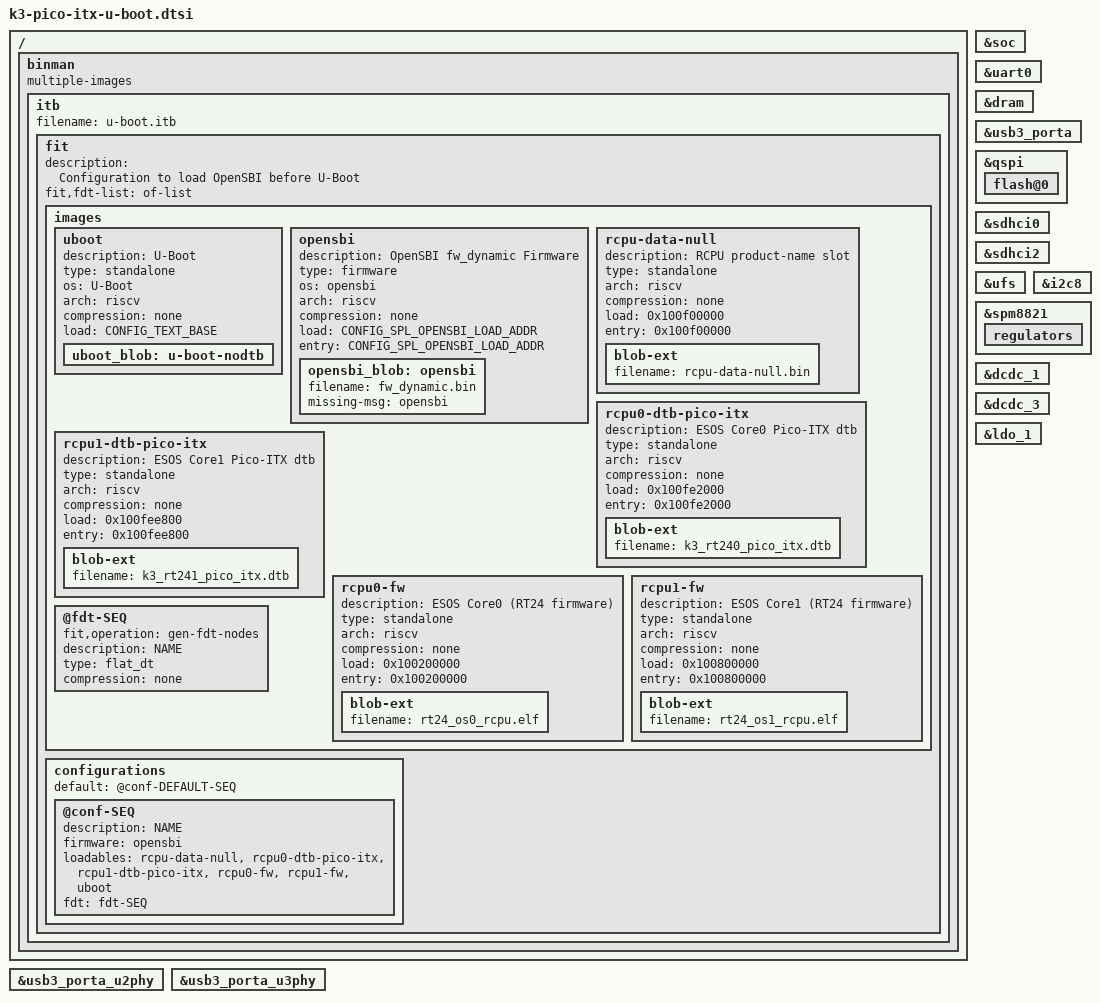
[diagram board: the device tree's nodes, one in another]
// SPDX-License-Identifier: GPL-2.0+ OR MIT
/*
 * Copyright (C) 2025-2026, Spacemit
 *
 * binman description for the SpacemiT K3 (X100) U-Boot FIT (u-boot.itb).
 * The SPL (M-mode, after DDR init) loads this FIT, which carries the OpenSBI
 * fw_dynamic firmware, U-Boot proper as a loadable and the K3 control FDT.
 * Boot chain: SPL -> u-boot.itb -> OpenSBI (M-mode) -> U-Boot proper (S-mode).
 */

#include <config.h>

/*
 * Tag the nodes the SPL (XPL) needs with "bootph-all" so fdtgrep keeps them
 * in the filtered SPL device tree. Upstream U-Boot uses the standardized
 * bootph-* markers (bootph-all = every phase, bootph-pre-ram = SPL); the
 * vendor 2022.10 tree used the old "u-boot,dm-spl", which this fdtgrep
 * ignores. Without these the SPL DTB is stripped to the root node, the DM
 * console never binds (silent SPL) and the DDR UCLASS_RAM probe finds no
 * controller node.
 */
&soc {
	bootph-all;
};

&uart0 {
	bootph-all;
};

&dram {
	bootph-all;
};

&usb3_porta_u2phy {
	bootph-all;
};

&usb3_porta_u3phy {
	bootph-all;
};

&usb3_porta {
	bootph-all;
	/*
	 * The K3 reset controller shares the CCU register base (d4050000) and is
	 * deliberately kept out of the SPL (probing it there disturbs the DDR
	 * clock), so RESET_USB3_PORTA has no provider in the SPL. The BROM already
	 * brought this port out of reset to download the FSBL over USB, so drop
	 * the reset dependency here; otherwise dwc3-generic's reset_get_bulk()
	 * fails and the fastboot gadget never probes.
	 */
	/delete-property/ resets;
	/delete-property/ reset-names;
};

&qspi {
	bootph-all;

	flash@0 {
		bootph-all;
	};
};

&sdhci0 {
	bootph-all;
};

&sdhci2 {
	bootph-all;
};

&ufs {
	bootph-all;
};

&i2c8 {
	bootph-all;
};

&spm8821 {
	bootph-all;

	regulators {
		bootph-all;
	};
};

&dcdc_1 {
	bootph-all;
};

&dcdc_3 {
	bootph-all;
};

&ldo_1 {
	bootph-all;
};

/ {
	binman: binman {
		multiple-images;
	};
};

&binman {
	itb {
		filename = "u-boot.itb";

		fit {
			description = "Configuration to load OpenSBI before U-Boot";
			#address-cells = <2>;
			fit,fdt-list = "of-list";

			images {
				uboot {
					description = "U-Boot";
					type = "standalone";
					os = "U-Boot";
					arch = "riscv";
					compression = "none";
					load = /bits/ 64 <CONFIG_TEXT_BASE>;

					uboot_blob: u-boot-nodtb {
					};
				};

				opensbi {
					description = "OpenSBI fw_dynamic Firmware";
					type = "firmware";
					os = "opensbi";
					arch = "riscv";
					compression = "none";
					load = /bits/ 64 <CONFIG_SPL_OPENSBI_LOAD_ADDR>;
					entry = /bits/ 64 <CONFIG_SPL_OPENSBI_LOAD_ADDR>;

					opensbi_blob: opensbi {
						filename = "fw_dynamic.bin";
						missing-msg = "opensbi";
					};
				};

				/*
				 * RCPU (ESOS) payloads, started by the SPL before
				 * OpenSBI so a live RPMI agent answers the MPXY
				 * device-power probe. The vendor ships them in a
				 * separate esos.itb; here binman packs them into
				 * u-boot.itb as extra loadables. Node names are
				 * load-bearing: the SPL FIT post-process hook
				 * matches "rcpu0-fw"/"rcpu1-fw" (rproc_load+start,
				 * generic copy skipped) and "rcpu-data-null"
				 * (product-name slot the ESOS matches against the
				 * /model of its dtbs). The dtb load addresses are
				 * the fixed vendor slots from esos.itb.
				 */
				rcpu-data-null {
					description = "RCPU product-name slot";
					type = "standalone";
					arch = "riscv";
					compression = "none";
					load = /bits/ 64 <0x100f00000>;
					entry = /bits/ 64 <0x100f00000>;

					blob-ext {
						filename = "rcpu-data-null.bin";
					};
				};

				rcpu0-dtb-pico-itx {
					description = "ESOS Core0 Pico-ITX dtb";
					type = "standalone";
					arch = "riscv";
					compression = "none";
					load = /bits/ 64 <0x100fe2000>;
					entry = /bits/ 64 <0x100fe2000>;

					blob-ext {
						filename = "k3_rt240_pico_itx.dtb";
					};
				};

				rcpu1-dtb-pico-itx {
					description = "ESOS Core1 Pico-ITX dtb";
					type = "standalone";
					arch = "riscv";
					compression = "none";
					load = /bits/ 64 <0x100fee800>;
					entry = /bits/ 64 <0x100fee800>;

					blob-ext {
						filename = "k3_rt241_pico_itx.dtb";
					};
				};

				rcpu0-fw {
					description = "ESOS Core0 (RT24 firmware)";
					type = "standalone";
					arch = "riscv";
					compression = "none";
					load = /bits/ 64 <0x100200000>;
					entry = /bits/ 64 <0x100200000>;

					blob-ext {
						filename = "rt24_os0_rcpu.elf";
					};
				};

				rcpu1-fw {
					description = "ESOS Core1 (RT24 firmware)";
					type = "standalone";
					arch = "riscv";
					compression = "none";
					load = /bits/ 64 <0x100800000>;
					entry = /bits/ 64 <0x100800000>;

					blob-ext {
						filename = "rt24_os1_rcpu.elf";
					};
				};

				@fdt-SEQ {
					fit,operation = "gen-fdt-nodes";
					description = "NAME";
					type = "flat_dt";
					compression = "none";
				};
			};

			configurations {
				default = "@conf-DEFAULT-SEQ";

				@conf-SEQ {
					description = "NAME";
					firmware = "opensbi";
					/* data + dtbs before the fw (the ESOS reads
					 * them at start); uboot last (vendor rule). */
					loadables = "rcpu-data-null",
						    "rcpu0-dtb-pico-itx",
						    "rcpu1-dtb-pico-itx",
						    "rcpu0-fw", "rcpu1-fw",
						    "uboot";
					fdt = "fdt-SEQ";
				};
			};
		};
	};
};
